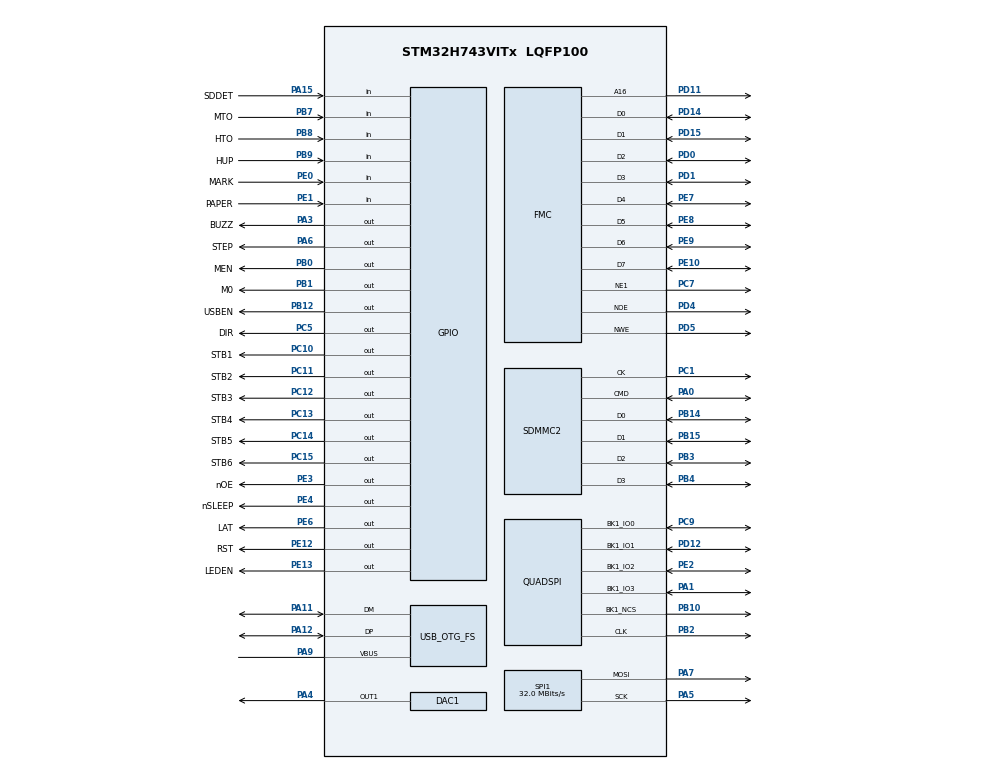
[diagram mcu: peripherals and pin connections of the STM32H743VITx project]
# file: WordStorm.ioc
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CORTEX_M7.default_mode_Activation=1
DAC1.DAC_Channel-DAC_OUT1=DAC_CHANNEL_1
FATFS.BSP.number=1
FATFS0.BSP.STBoard=false
FATFS0.BSP.api=Unknown
FATFS0.BSP.instance=PA15 (JTDI)
FATFS0.BSP.ip=GPIO
FATFS0.BSP.mode=Input
FATFS0.BSP.name=Detect_SDIO
FATFS0.BSP.solution=PA15 (JTDI)
Mcu.Family=STM32H7
Mcu.Name=STM32H743VITx
Mcu.Package=LQFP100
NVIC.OTG_FS_IRQn=true\:0\:0\:false\:false\:true\:false\:true\:true
NVIC.PriorityGroup=NVIC_PRIORITYGROUP_4
PA0.Mode=SD_4_bits_Wide_bus
PA0.Signal=SDMMC2_CMD
PA1.Mode=Single Bank 1
PA1.Signal=QUADSPI_BK1_IO3
PA11.Mode=Host_Only
PA11.Signal=USB_OTG_FS_DM
PA12.Mode=Host_Only
PA12.Signal=USB_OTG_FS_DP
PA13\ (JTMS/SWDIO).Mode=Serial_Wire
PA13\ (JTMS/SWDIO).Signal=DEBUG_JTMS-SWDIO
PA14\ (JTCK/SWCLK).Mode=Serial_Wire
PA14\ (JTCK/SWCLK).Signal=DEBUG_JTCK-SWCLK
PA15\ (JTDI).GPIO_Label=SDDET
PA15\ (JTDI).Signal=GPIO_Input
PA3.GPIO_Label=BUZZ
PA3.Signal=GPIO_Output
PA4.Signal=COMP_DAC11_group
PA5.Mode=TX_Only_Simplex_Unidirect_Master
PA5.Signal=SPI1_SCK
PA6.GPIO_Label=STEP
PA6.Signal=GPIO_Output
PA7.Mode=TX_Only_Simplex_Unidirect_Master
PA7.Signal=SPI1_MOSI
PA9.Mode=Activate_VBUS
PA9.Signal=USB_OTG_FS_VBUS
PB0.GPIO_Label=MEN
PB0.Signal=GPIO_Output
PB1.GPIO_Label=M0
PB1.Signal=GPIO_Output
PB10.Mode=Single Bank 1
PB10.Signal=QUADSPI_BK1_NCS
PB12.GPIO_Label=USBEN
PB12.Signal=GPIO_Output
PB14.Mode=SD_4_bits_Wide_bus
PB14.Signal=SDMMC2_D0
PB15.Mode=SD_4_bits_Wide_bus
PB15.Signal=SDMMC2_D1
PB2.Mode=Single Bank 1
PB2.Signal=QUADSPI_CLK
PB3\ (JTDO/TRACESWO).Mode=SD_4_bits_Wide_bus
PB3\ (JTDO/TRACESWO).Signal=SDMMC2_D2
PB4\ (NJTRST).Mode=SD_4_bits_Wide_bus
PB4\ (NJTRST).Signal=SDMMC2_D3
PB7.GPIO_Label=MTO
PB7.Signal=GPIO_Input
PB8.GPIO_Label=HTO
PB8.Signal=GPIO_Input
PB9.GPIO_Label=HUP
PB9.Signal=GPIO_Input
PC1.Mode=SD_4_bits_Wide_bus
PC1.Signal=SDMMC2_CK
PC10.GPIO_Label=STB1
PC10.Signal=GPIO_Output
PC11.GPIO_Label=STB2
PC11.Signal=GPIO_Output
PC12.GPIO_Label=STB3
PC12.Signal=GPIO_Output
PC13.GPIO_Label=STB4
PC13.Signal=GPIO_Output
PC14-OSC32_IN\ (OSC32_IN).GPIO_Label=STB5
PC14-OSC32_IN\ (OSC32_IN).Signal=GPIO_Output
PC15-OSC32_OUT\ (OSC32_OUT).GPIO_Label=STB6
PC15-OSC32_OUT\ (OSC32_OUT).Signal=GPIO_Output
PC5.GPIO_Label=DIR
PC5.Signal=GPIO_Output
PC7.Mode=NorPsramChipSelect1_1
PC7.Signal=FMC_NE1
PC9.Mode=Single Bank 1
PC9.Signal=QUADSPI_BK1_IO0
PD0.Signal=FMC_D2_DA2
PD1.Signal=FMC_D3_DA3
PD11.Signal=FMC_A16_CLE
PD12.Mode=Single Bank 1
PD12.Signal=QUADSPI_BK1_IO1
PD14.Signal=FMC_D0_DA0
PD15.Signal=FMC_D1_DA1
PD4.Signal=FMC_NOE
PD5.Signal=FMC_NWE
PE0.GPIO_Label=MARK
PE0.Signal=GPIO_Input
PE1.GPIO_Label=PAPER
PE1.Signal=GPIO_Input
PE10.Signal=FMC_D7_DA7
PE12.GPIO_Label=RST
PE12.Signal=GPIO_Output
PE13.GPIO_Label=LEDEN
PE13.Signal=GPIO_Output
PE2.Mode=Single Bank 1
PE2.Signal=QUADSPI_BK1_IO2
PE3.GPIO_Label=nOE
PE3.Signal=GPIO_Output
PE4.GPIO_Label=nSLEEP
PE4.Signal=GPIO_Output
PE6.GPIO_Label=LAT
PE6.Signal=GPIO_Output
PE7.Signal=FMC_D4_DA4
PE8.Signal=FMC_D5_DA5
PE9.Signal=FMC_D6_DA6
PH0-OSC_IN\ (PH0).Mode=HSE-External-Oscillator
PH0-OSC_IN\ (PH0).Signal=RCC_OSC_IN
PH1-OSC_OUT\ (PH1).Mode=HSE-External-Oscillator
PH1-OSC_OUT\ (PH1).Signal=RCC_OSC_OUT
ProjectManager.HeapSize=0x200
ProjectManager.StackSize=0x400
ProjectManager.TargetToolchain=STM32CubeIDE
RCC.ADCFreq_Value=16125000
RCC.APB1Freq_Value=120000000
RCC.APB2Freq_Value=120000000
RCC.APB3Freq_Value=120000000
RCC.APB4Freq_Value=120000000
RCC.CortexFreq_Value=480000000
RCC.D1PPRE=RCC_APB3_DIV2
RCC.D2PPRE1=RCC_APB1_DIV2
RCC.D2PPRE2=RCC_APB2_DIV2
RCC.D3PPRE=RCC_APB4_DIV2
RCC.DIVM1=1
RCC.DIVN1=120
RCC.DIVQ1=15
RCC.HCLKFreq_Value=240000000
RCC.HPRE=RCC_HCLK_DIV2
RCC.HSE_VALUE=8000000
RCC.PLL2FRACN=0
RCC.PLL3FRACN=0
RCC.PLLFRACN=0
RCC.SYSCLKFreq_VALUE=480000000
RCC.SYSCLKSource=RCC_SYSCLKSOURCE_PLLCLK
RCC.USBFreq_Value=64000000
SH.COMP_DAC11_group.0=DAC1_OUT1,DAC_OUT1
SH.FMC_A16_CLE.0=FMC_A16,A16_1
SH.FMC_D0_DA0.0=FMC_D0,8b-d1
SH.FMC_D1_DA1.0=FMC_D1,8b-d1
SH.FMC_D2_DA2.0=FMC_D2,8b-d1
SH.FMC_D3_DA3.0=FMC_D3,8b-d1
SH.FMC_D4_DA4.0=FMC_D4,8b-d1
SH.FMC_D5_DA5.0=FMC_D5,8b-d1
SH.FMC_D6_DA6.0=FMC_D6,8b-d1
SH.FMC_D7_DA7.0=FMC_D7,8b-d1
SH.FMC_NOE.0=FMC_NOE,Lcd1
SH.FMC_NWE.0=FMC_NWE,Lcd1
SPI1.CalculateBaudRate=32.0 MBits/s
SPI1.Direction=SPI_DIRECTION_2LINES_TXONLY
SPI1.Mode=SPI_MODE_MASTER
SPI1.VirtualType=VM_MASTER
USB_HOST.BSP.number=1
USB_HOST.USBH_HandleTypeDef-HID_FS=hUsbHostFS
USB_HOST.VirtualModeFS=Hid
USB_HOST0.BSP.STBoard=false
USB_HOST0.BSP.api=Unknown
USB_HOST0.BSP.condition=SW_VBUS_DRIVE_HID_FS \= false
USB_HOST0.BSP.instance=PB12
USB_HOST0.BSP.ip=GPIO
USB_HOST0.BSP.mode=Output
USB_HOST0.BSP.name=Drive_VBUS_FS
USB_HOST0.BSP.solution=PB12
USB_OTG_FS.VirtualMode=Host_Only
USB_OTG_FS.phy_itface=HCD_PHY_EMBEDDED
VP_FATFS_VS_SDIO.Mode=SDIO
VP_MEMORYMAP_VS_MEMORYMAP.Mode=CurAppReg
VP_USB_HOST_VS_USB_HOST_HID_FS.Mode=HID_FS
board=custom

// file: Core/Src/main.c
/* USER CODE BEGIN Header */
/**
  ******************************************************************************
  * @file           : main.c
  * @brief          : Main program body
  ******************************************************************************
  * @attention
  *
  * Copyright (c) 2024 STMicroelectronics.
  * All rights reserved.
  *
  * This software is licensed under terms that can be found in the LICENSE file
  * in the root directory of this software component.
  * If no LICENSE file comes with this software, it is provided AS-IS.
  *
  ******************************************************************************
  */
/* USER CODE END Header */
#include "main.h"
#include "dac.h"
#include "fatfs.h"
#include "memorymap.h"
#include "quadspi.h"
#include "sdmmc.h"
#include "spi.h"
#include "usb_host.h"
#include "gpio.h"
#include "fmc.h"

void SystemClock_Config(void);
static void MPU_Config(void);
void MX_USB_HOST_Process(void);

int main(void)
{

  /* MPU Configuration--------------------------------------------------------*/
  MPU_Config();

  /* MCU Configuration--------------------------------------------------------*/

  /* Reset of all peripherals, Initializes the Flash interface and the Systick. */
  HAL_Init();

  /* Configure the system clock */
  SystemClock_Config();

  /* Initialize all configured peripherals */
  MX_GPIO_Init();
  MX_DAC1_Init();
  MX_FMC_Init();
  MX_QUADSPI_Init();
  MX_SDMMC2_SD_Init();
  MX_USB_HOST_Init();
  MX_SPI1_Init();
  MX_FATFS_Init();

  /* Infinite loop */
  while (1)
  {
    MX_USB_HOST_Process();

    /* USER CODE BEGIN 3 */

    __ASM("NOP"); //breakpoint

  }
  /* USER CODE END 3 */
}

void SystemClock_Config(void)
{
  RCC_OscInitTypeDef RCC_OscInitStruct = {0};
  RCC_ClkInitTypeDef RCC_ClkInitStruct = {0};

  /** Supply configuration update enable
  */
  HAL_PWREx_ConfigSupply(PWR_LDO_SUPPLY);

  /** Configure the main internal regulator output voltage
  */
  __HAL_PWR_VOLTAGESCALING_CONFIG(PWR_REGULATOR_VOLTAGE_SCALE1);

  while(!__HAL_PWR_GET_FLAG(PWR_FLAG_VOSRDY)) {}

  __HAL_RCC_SYSCFG_CLK_ENABLE();
  __HAL_PWR_VOLTAGESCALING_CONFIG(PWR_REGULATOR_VOLTAGE_SCALE0);

  while(!__HAL_PWR_GET_FLAG(PWR_FLAG_VOSRDY)) {}

  /** Initializes the RCC Oscillators according to the specified parameters
  * in the RCC_OscInitTypeDef structure.
  */
  RCC_OscInitStruct.OscillatorType = RCC_OSCILLATORTYPE_HSE;
  RCC_OscInitStruct.HSEState = RCC_HSE_ON;
  RCC_OscInitStruct.PLL.PLLState = RCC_PLL_ON;
  RCC_OscInitStruct.PLL.PLLSource = RCC_PLLSOURCE_HSE;
  RCC_OscInitStruct.PLL.PLLM = 1;
  RCC_OscInitStruct.PLL.PLLN = 120;
  RCC_OscInitStruct.PLL.PLLP = 2;
  RCC_OscInitStruct.PLL.PLLQ = 15;
  RCC_OscInitStruct.PLL.PLLR = 2;
  RCC_OscInitStruct.PLL.PLLRGE = RCC_PLL1VCIRANGE_3;
  RCC_OscInitStruct.PLL.PLLVCOSEL = RCC_PLL1VCOWIDE;
  RCC_OscInitStruct.PLL.PLLFRACN = 0;
  if (HAL_RCC_OscConfig(&RCC_OscInitStruct) != HAL_OK)
  {
    Error_Handler();
  }

  /** Initializes the CPU, AHB and APB buses clocks
  */
  RCC_ClkInitStruct.ClockType = RCC_CLOCKTYPE_HCLK|RCC_CLOCKTYPE_SYSCLK
                              |RCC_CLOCKTYPE_PCLK1|RCC_CLOCKTYPE_PCLK2
                              |RCC_CLOCKTYPE_D3PCLK1|RCC_CLOCKTYPE_D1PCLK1;
  RCC_ClkInitStruct.SYSCLKSource = RCC_SYSCLKSOURCE_PLLCLK;
  RCC_ClkInitStruct.SYSCLKDivider = RCC_SYSCLK_DIV1;
  RCC_ClkInitStruct.AHBCLKDivider = RCC_HCLK_DIV2;
  RCC_ClkInitStruct.APB3CLKDivider = RCC_APB3_DIV2;
  RCC_ClkInitStruct.APB1CLKDivider = RCC_APB1_DIV2;
  RCC_ClkInitStruct.APB2CLKDivider = RCC_APB2_DIV2;
  RCC_ClkInitStruct.APB4CLKDivider = RCC_APB4_DIV2;

  if (HAL_RCC_ClockConfig(&RCC_ClkInitStruct, FLASH_LATENCY_4) != HAL_OK)
  {
    Error_Handler();
  }
}

 /* MPU Configuration */

void MPU_Config(void)
{
  MPU_Region_InitTypeDef MPU_InitStruct = {0};

  /* Disables the MPU */
  HAL_MPU_Disable();

  /** Initializes and configures the Region and the memory to be protected
  */
  MPU_InitStruct.Enable = MPU_REGION_ENABLE;
  MPU_InitStruct.Number = MPU_REGION_NUMBER0;
  MPU_InitStruct.BaseAddress = 0x0;
  MPU_InitStruct.Size = MPU_REGION_SIZE_4GB;
  MPU_InitStruct.SubRegionDisable = 0x87;
  MPU_InitStruct.TypeExtField = MPU_TEX_LEVEL0;
  MPU_InitStruct.AccessPermission = MPU_REGION_NO_ACCESS;
  MPU_InitStruct.DisableExec = MPU_INSTRUCTION_ACCESS_DISABLE;
  MPU_InitStruct.IsShareable = MPU_ACCESS_SHAREABLE;
  MPU_InitStruct.IsCacheable = MPU_ACCESS_NOT_CACHEABLE;
  MPU_InitStruct.IsBufferable = MPU_ACCESS_NOT_BUFFERABLE;

  HAL_MPU_ConfigRegion(&MPU_InitStruct);
  /* Enables the MPU */
  HAL_MPU_Enable(MPU_PRIVILEGED_DEFAULT);

}

void Error_Handler(void)
{
  __disable_irq();
  while (1)
  {
  }
}
